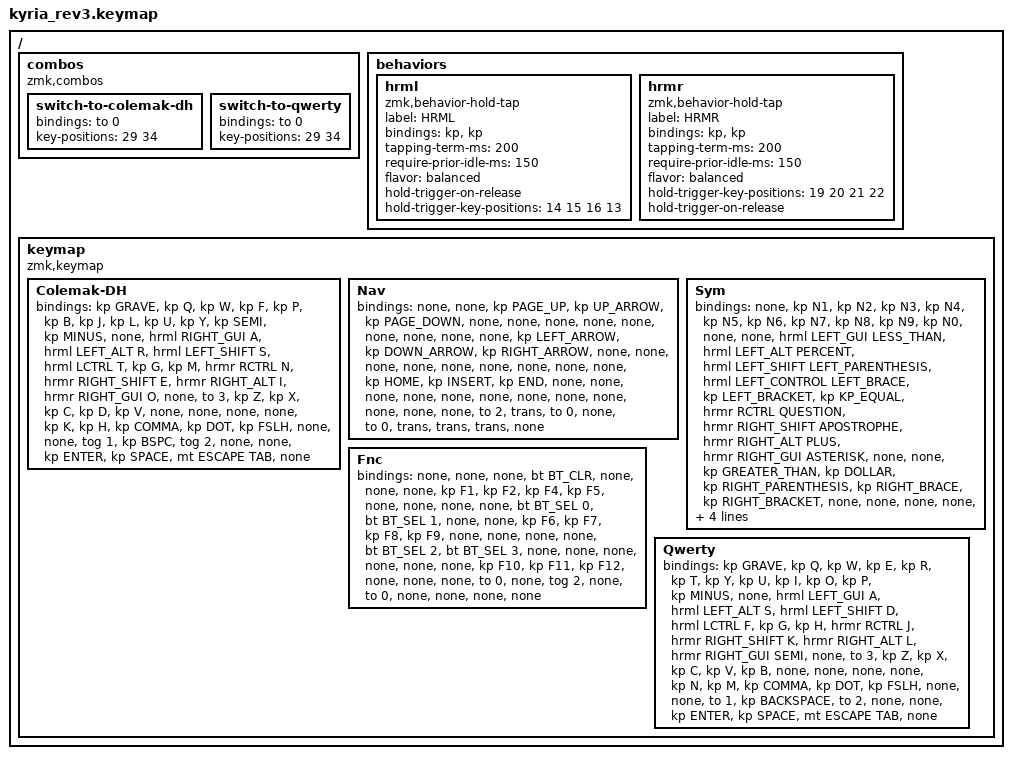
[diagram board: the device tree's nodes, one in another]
/*
 * Copyright (c) 2023 The ZMK Contributors
 *
 * SPDX-License-Identifier: MIT
 */

#include <behaviors.dtsi>
#include <dt-bindings/zmk/bt.h>
#include <dt-bindings/zmk/keys.h>

/* Uncomment this block if using RGB
&led_strip {
    chain-length = <6>;
    // chain-length = <31>; // Uncomment if using both per-key and underglow LEDs
    // chain-length = <25>; // Uncomment if using only per-key LEDs.
};
 */

/ {
    combos {
        compatible = "zmk,combos";

        switch-to-colemak-dh {
            bindings = <&to 0>;
            key-positions = <29 34>;
        };

        switch-to-qwerty {
            bindings = <&to 0>;
            key-positions = <29 34>;
        };
    };

    behaviors {
        hrml: hrml {
            compatible = "zmk,behavior-hold-tap";
            label = "HRML";
            bindings = <&kp>, <&kp>;

            #binding-cells = <2>;
            tapping-term-ms = <200>;
            require-prior-idle-ms = <150>;
            flavor = "balanced";
            hold-trigger-on-release;
            hold-trigger-key-positions = <14 15 16 13>;
        };

        hrmr: hrmr {
            compatible = "zmk,behavior-hold-tap";
            label = "HRMR";
            bindings = <&kp>, <&kp>;

            #binding-cells = <2>;
            tapping-term-ms = <200>;
            require-prior-idle-ms = <150>;
            flavor = "balanced";
            hold-trigger-key-positions = <19 20 21 22>;
            hold-trigger-on-release;
        };
    };

    keymap {
        compatible = "zmk,keymap";

        Colemak-DH {
            bindings = <
&kp GRAVE  &kp Q  &kp W  &kp F  &kp P  &kp B  &kp J  &kp L  &kp U  &kp Y  &kp SEMI  &kp MINUS  &none  &hrml RIGHT_GUI A  &hrml LEFT_ALT R  &hrml LEFT_SHIFT S  &hrml LCTRL T  &kp G  &kp M  &hrmr RCTRL N  &hrmr RIGHT_SHIFT E  &hrmr RIGHT_ALT I  &hrmr RIGHT_GUI O  &none  &to 3  &kp Z  &kp X  &kp C  &kp D  &kp V  &none  &none  &none  &none  &kp K  &kp H  &kp COMMA  &kp DOT  &kp FSLH  &none  &none  &tog 1  &kp BSPC  &tog 2  &none  &none  &kp ENTER  &kp SPACE  &mt ESCAPE TAB  &none
            >;
        };

        Nav {
            bindings = <
&none  &none  &kp PAGE_UP  &kp UP_ARROW  &kp PAGE_DOWN  &none  &none  &none  &none  &none  &none  &none  &none  &none  &kp LEFT_ARROW  &kp DOWN_ARROW  &kp RIGHT_ARROW  &none  &none  &none  &none  &none  &none  &none  &none  &none  &kp HOME  &kp INSERT  &kp END  &none  &none  &none  &none  &none  &none  &none  &none  &none  &none  &none  &none  &to 2  &trans  &to 0  &none  &to 0  &trans  &trans  &trans  &none
            >;
        };

        Sym {
            bindings = <
&none  &kp N1  &kp N2  &kp N3  &kp N4  &kp N5  &kp N6  &kp N7  &kp N8  &kp N9  &kp N0  &none  &none  &hrml LEFT_GUI LESS_THAN  &hrml LEFT_ALT PERCENT  &hrml LEFT_SHIFT LEFT_PARENTHESIS  &hrml LEFT_CONTROL LEFT_BRACE  &kp LEFT_BRACKET  &kp KP_EQUAL  &hrmr RCTRL QUESTION  &hrmr RIGHT_SHIFT APOSTROPHE  &hrmr RIGHT_ALT PLUS  &hrmr RIGHT_GUI ASTERISK  &none  &none  &kp GREATER_THAN  &kp DOLLAR  &kp RIGHT_PARENTHESIS  &kp RIGHT_BRACE  &kp RIGHT_BRACKET  &none  &none  &none  &none  &kp AT_SIGN  &kp KP_EQUAL  &kp DOUBLE_QUOTES  &kp KP_MINUS  &kp BACKSLASH  &none  &none  &to 1  &trans  &to 0  &none  &to 0  &trans  &trans  &trans  &none
            >;
        };

        Fnc {
            // ---------------------------------------------------------------------------------------------------------------------------------
            // |       |      |BT_CLR|BTSEL0|BTSEL1|BTSEL2|                                         |      |      |      |      |      |      |
            // |       |      |      |BTSEL3|BTSEL4|      |                                         |      |      |      |      |      |      |
            // |       |      |      |      |      |      |      |      |      |      |      |      |      |      |      |      |      |      |
            //                       |      |      |      |      |      |      |      |      |      |      |      |      |

            bindings = <
&none  &none  &none  &bt BT_CLR  &none  &none  &none  &kp F1  &kp F2  &kp F4  &kp F5  &none  &none  &none  &none  &bt BT_SEL 0  &bt BT_SEL 1  &none  &none  &kp F6  &kp F7  &kp F8  &kp F9  &none  &none  &none  &none  &bt BT_SEL 2  &bt BT_SEL 3  &none  &none  &none  &none  &none  &none  &kp F10  &kp F11  &kp F12  &none  &none  &none  &to 0  &none  &tog 2  &none  &to 0  &none  &none  &none  &none
            >;
        };

        Qwerty {
            // ---------------------------------------------------------------------------------------------------------------------------------
            // |  ESC  |  Q  |  W  |  E   |  R   |  T   |                                          |  Y   |  U    |  I    |  O   |   P   |   \  |
            // |  TAB  |  A  |  S  |  D   |  F   |  G   |                                          |  H   |  J    |  K    |  L   |   ;   |   '  |
            // | SHIFT |  Z  |  X  |  C   |  V   |  B   | L SHIFT | L SHIFT |  | LAYER 1 | L SHIFT |  N   |  M    |  ,    |  .   |   /   | CTRL |
            //                     | GUI  | DEL  | RET  |  SPACE  |   ESC   |  |   RET   |  SPACE  | TAB  | BSPC  | R-ALT |

            bindings = <
&kp GRAVE  &kp Q  &kp W  &kp E  &kp R  &kp T  &kp Y  &kp U  &kp I  &kp O  &kp P  &kp MINUS  &none  &hrml LEFT_GUI A  &hrml LEFT_ALT S  &hrml LEFT_SHIFT D  &hrml LCTRL F  &kp G  &kp H  &hrmr RCTRL J  &hrmr RIGHT_SHIFT K  &hrmr RIGHT_ALT L  &hrmr RIGHT_GUI SEMI  &none  &to 3  &kp Z  &kp X  &kp C  &kp V  &kp B  &none  &none  &none  &none  &kp N  &kp M  &kp COMMA  &kp DOT  &kp FSLH  &none  &none  &to 1  &kp BACKSPACE  &to 2  &none  &none  &kp ENTER  &kp SPACE  &mt ESCAPE TAB  &none
            >;
        };
    };
};
